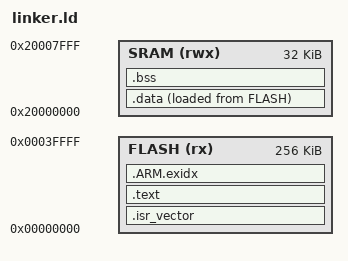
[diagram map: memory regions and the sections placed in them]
/* TM4C123GH6PM: 256 KB flash at 0x00000000, 32 KB SRAM at 0x20000000 */
ENTRY(Reset_Handler)

MEMORY
{
    FLASH (rx)  : ORIGIN = 0x00000000, LENGTH = 256K
    SRAM  (rwx) : ORIGIN = 0x20000000, LENGTH = 32K
}

_estack = ORIGIN(SRAM) + LENGTH(SRAM);

SECTIONS
{
    .isr_vector :
    {
        KEEP(*(.isr_vector))
    } > FLASH

    .text :
    {
        *(.text*)
        *(.rodata*)
        . = ALIGN(4);
    } > FLASH

    .ARM.exidx :
    {
        *(.ARM.exidx*)
    } > FLASH

    _sidata = LOADADDR(.data);

    .data :
    {
        . = ALIGN(4);
        _sdata = .;
        *(.data*)
        . = ALIGN(4);
        _edata = .;
    } > SRAM AT > FLASH

    .bss (NOLOAD) :
    {
        . = ALIGN(4);
        _sbss = .;
        *(.bss*)
        *(COMMON)
        . = ALIGN(4);
        _ebss = .;
    } > SRAM
}
